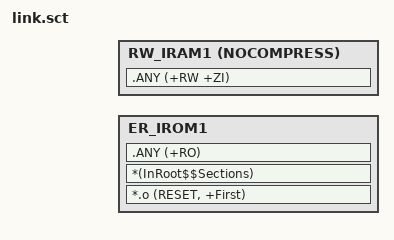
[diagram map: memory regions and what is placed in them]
#! armclang -E --target=arm-arm-none-eabi -mcpu=cortex-m33 -xc -I $SDK_ROOT/drivers/cmsis/sf32lb58x
#include "rtconfig.h"
#include "mem_map.h"


; *************************************************************
; *** Scatter-Loading Description File generated by uVision ***
; *************************************************************


LR_IROM1 ACPU_CODE_REGION1_START_ADDR ACPU_CODE_REGION1_SIZE  {    ; load region size_region
  ER_IROM1 ACPU_CODE_REGION1_START_ADDR ACPU_CODE_REGION1_SIZE  {  ; load address = execution address
   *.o (RESET, +First)
   *(InRoot$$Sections)
   .ANY (+RO)
  }
  RW_IRAM1 AlignExpr(ACPU_CODE_REGION1_SBUS_START_ADDR+ImageLength(ER_IROM1), 16) ALIGN 16 NOCOMPRESS  {  ; RW data
   .ANY (+RW +ZI)
  }
  ; Load Address must be equal to Exec Address
  ScatterAssert((LoadBase(RW_IRAM1) OR HPSYS_RAM6_BASE) == ImageBase(RW_IRAM1))
  ScatterAssert((ImageLength(ER_IROM1)+ImageLength(RW_IRAM1))<ACPU_CODE_REGION1_SIZE)
}


;LR_IROM2 ACPU_CODE_REGION2_START_ADDR ACPU_CODE_REGION2_SIZE  {    ; load region size_region
;  ER_IROM2 ACPU_CODE_REGION2_START_ADDR ACPU_CODE_REGION2_SIZE  {  ; load address = execution address
;    *.o (.text.HAL_PMU_EnableXTAL32)
;  }
;}
